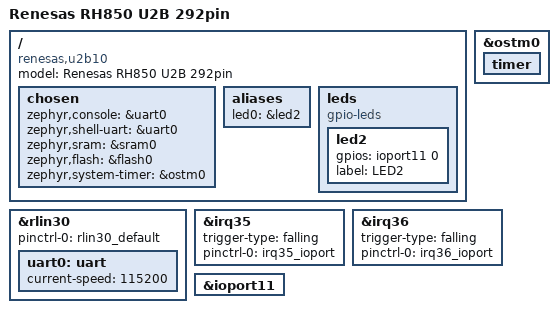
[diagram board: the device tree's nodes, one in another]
/*
 * Copyright (c) 2026 Renesas Electronics Corporation
 * SPDX-License-Identifier: Apache-2.0
 */

/dts-v1/;

#include <rh850/renesas/rh850u2b/r7f70254xafabb-c.dtsi>
#include <dt-bindings/gpio/gpio.h>

#include "pb_rh850u2b_292pin-pinctrl.dtsi"

/ {
	model = "Renesas RH850 U2B 292pin";
	compatible = "renesas,u2b10", "renesas,u2b";

	chosen {
		zephyr,console = &uart0;
		zephyr,shell-uart = &uart0;
		zephyr,sram = &sram0;
		zephyr,flash = &flash0;
		zephyr,system-timer = &ostm0;
	};

	aliases {
		led0 = &led2;
	};

	leds {
		compatible = "gpio-leds";

		led2: led2 {
			gpios = <&ioport11 0 GPIO_ACTIVE_HIGH>;
			label = "LED2";
		};
	};
};

&ostm0 {
	status = "okay";

	timer {
		status = "okay";
	};
};

&rlin30 {
	pinctrl-0 = <&rlin30_default>;
	pinctrl-names = "default";
	status = "okay";

	uart0: uart {
		current-speed = <115200>;
		status = "okay";
	};
};

&irq35 {
	trigger-type = "falling";
	pinctrl-0 = <&irq35_ioport>;
	pinctrl-names = "default";
	status = "okay";
};

&irq36 {
	trigger-type = "falling";
	pinctrl-0 = <&irq36_ioport>;
	pinctrl-names = "default";
	status = "okay";
};

&ioport11 {
	status = "okay";
};
